AUTOSAR XML (schema 00051)
package /ComponentTypes
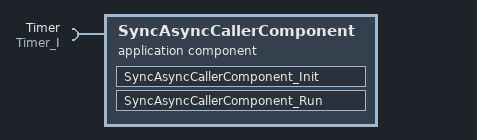
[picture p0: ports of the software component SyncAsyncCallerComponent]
  application sw component type SyncAsyncCallerComponent
    require port Timer: required-interface=Timer_I
    behavior SyncAsyncCallerComponent_InternalBehavior
      runnable SyncAsyncCallerComponent_Init
      runnable SyncAsyncCallerComponent_Run
        async call SC_Timer_GetTime: operation=Timer.GetTime
        sync call SC_Timer_IsTimerElapsed: operation=Timer.IsTimerElapsed
  swc implementation SyncAsyncCallerComponent_Implementation: behavior=SyncAsyncCallerComponent_InternalBehavior
